# MKM34Z5 register map
File version: 1.6
Registers are 8-bit, read-write, reset 0x0 unless marked. A register's access mark holds for its fields unless they carry their own. Offsets are from the block's base; [hi:lo] are bit positions; {n}, {i} and the like mark numbered series; 'fields as' and 'values as' point back to an identical list.

## DMA — DMA Controller
Base 0x40008000; register names take the prefix DMA_
{0x100+0x10*i} SAR{i} (i=0..3) 32-bit — Source Address Register
  [31:0] SAR
{0x104+0x10*i} DAR{i} (i=0..3) 32-bit — Destination Address Register
  [31:0] DAR
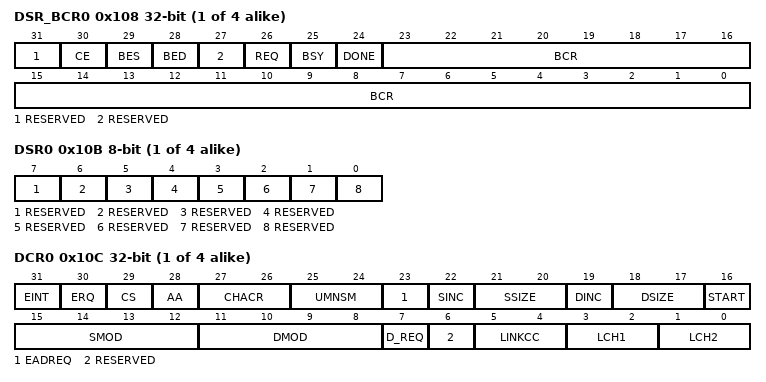
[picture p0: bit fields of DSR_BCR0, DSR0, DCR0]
{0x108+0x10*i} DSR_BCR{i} (i=0..3) 32-bit — DMA Status Register / Byte Count Register
  [31] RESERVED ro
  [30] CE ro — Configuration error
    0=No configuration error exists; 1=A configuration error has occurred
  [29] BES ro — Bus error on source
    0=No bus error occurred; 1=The DMA channel terminated with a bus error during the read portion of a transfer
  [28] BED ro — Bus error on destination
    0=No bus error occurred; 1=The DMA channel terminated with a bus error during the write portion of a transfer
  [27] RESERVED ro
  [26] REQ ro — Request
    0=No request is pending or the channel is currently active. Cleared when the channel is selected.; 1=The DMA channel has a transfer remaining and the channel is not selected
  [25] BSY ro — Busy
    0=DMA channel is inactive. Cleared when the DMA has finished the last transaction.; 1=BSY is set the first time the channel is enabled after a transfer is initiated
  [24] DONE — Transactions done
    0=DMA transfer is not yet complete. Writing a 0 has no effect.; 1=DMA transfer completed. Writing a 1 to this bit clears all DMA status bits and should be used in an interrupt service routine to clear the DMA interrupt and error bits.
  [23:0] BCR
{0x10B+0x10*i} DSR{i} (i=0..3) — DMA_DSR{i} register.
  [7] RESERVED ro
  [6] RESERVED ro — Configuration error.
    values as DSR_BCR0.CE
  [5] RESERVED ro — Bus error on source.
    values as DSR_BCR0.BES
  [4] RESERVED ro — Bus error on destination.
    values as DSR_BCR0.BED
  [3] RESERVED ro
  [2] RESERVED ro — Request.
    0=No request is pending or the channel is currently active; 1=The DMA channel has a transfer remaining and the channel is not selected
  [1] RESERVED ro — Busy.
    0=DMA channel is inactive; 1=BSY is set the first time the channel is enabled after a transfer is initiated
  [0] RESERVED — Transactions done.
    0=DMA transfer is not yet complete; 1=DMA transfer completed
{0x10C+0x10*i} DCR{i} (i=0..3) 32-bit — DMA Control Register
  [31] EINT — Enable interrupt on completion of transfer
    0=No interrupt is generated; 1=Interrupt signal is enabled
  [30] ERQ — Enable peripheral request
    0=Peripheral request is ignored; 1=Enables peripheral request to initiate transfer. A software-initiated request (setting the START bit) is always enabled.
  [29] CS — Cycle steal
    0=DMA continuously makes read/write transfers until the BCR decrements to 0; 1=Forces a single read/write transfer per request
  [28] AA — Auto-align
    0=Auto-align disabled; 1=If SSIZE indicates a transfer no smaller than DSIZE, source accesses are auto-aligned; otherwise, destination accesses are auto-aligned. Source alignment takes precedence over destination alignment. If auto-alignment is enabled, the appropriate address register increments, regardless of DINC or SINC.
  [27:26] CHACR — Channel Access Control
  [25:24] UMNSM — User Mode, Nonsecure Mode
    0=Channel attributes are set to the current mode; 1=If the current mode is privileged and secure, then attributes are set to {privileged, secure}. Otherwise, writing this value terminates in an error.; 2=If the current mode is privileged and secure or if the current mode is user and secure, then attributes are set to {user, secure}. Otherwise, writing this value terminates in an error.; 3=If the current mode is privileged and secure, user and secure, or user and nonsecure, then attributes are set to {user, nonsecure}
  [23] EADREQ — Enable asynchronous DMA requests
    0=Disabled; 1=Enabled
  [22] SINC — Source increment
    0=No change to SAR after a successful transfer; 1=The SAR increments by 1, 2, 4 as determined by the transfer size
  [21:20] SSIZE — Source size
    0=32-bit; 1=8-bit; 2=16-bit
  [19] DINC — Destination increment
    0=No change to the DAR after a successful transfer; 1=The DAR increments by 1, 2, 4 depending upon the size of the transfer
  [18:17] DSIZE — Destination size
    0=32-bit; 1=8-bit; 2=16-bit
  [16] START wo — Start transfer
    0=DMA inactive; 1=The DMA begins the transfer in accordance to the values in the TCDn. START is cleared automatically after one module clock and always reads as logic 0.
  [15:12] SMOD — Source address modulo
    0=Buffer disabled; 1=Circular buffer size is 16 bytes; 2=Circular buffer size is 32 bytes; 3=Circular buffer size is 64 bytes; 4=Circular buffer size is 128 bytes; 5=Circular buffer size is 256 bytes; 6=Circular buffer size is 512 bytes; 7=Circular buffer size is 1 KB; 8=Circular buffer size is 2 KB; 9=Circular buffer size is 4 KB; 10=Circular buffer size is 8 KB; 11=Circular buffer size is 16 KB; 12=Circular buffer size is 32 KB; 13=Circular buffer size is 64 KB; 14=Circular buffer size is 128 KB; 15=Circular buffer size is 256 KB
  [11:8] DMOD — Destination address modulo
    values as SMOD
  [7] D_REQ — Disable request
    0=ERQ bit is not affected; 1=ERQ bit is cleared when the BCR is exhausted
  [6] RESERVED ro
  [5:4] LINKCC — Link channel control
    0=No channel-to-channel linking; 1=Perform a link to channel LCH1 after each cycle-steal transfer followed by a link to LCH2 after the BCR decrements to zero; 2=Perform a link to channel LCH1 after each cycle-steal transfer; 3=Perform a link to channel LCH1 after the BCR decrements to zero
  [3:2] LCH1 — Link channel 1
    {v}=DMA Channel {v} (v=0..3)
  [1:0] LCH2 — Link channel 2
    {v}=DMA Channel {v} (v=0..3)
